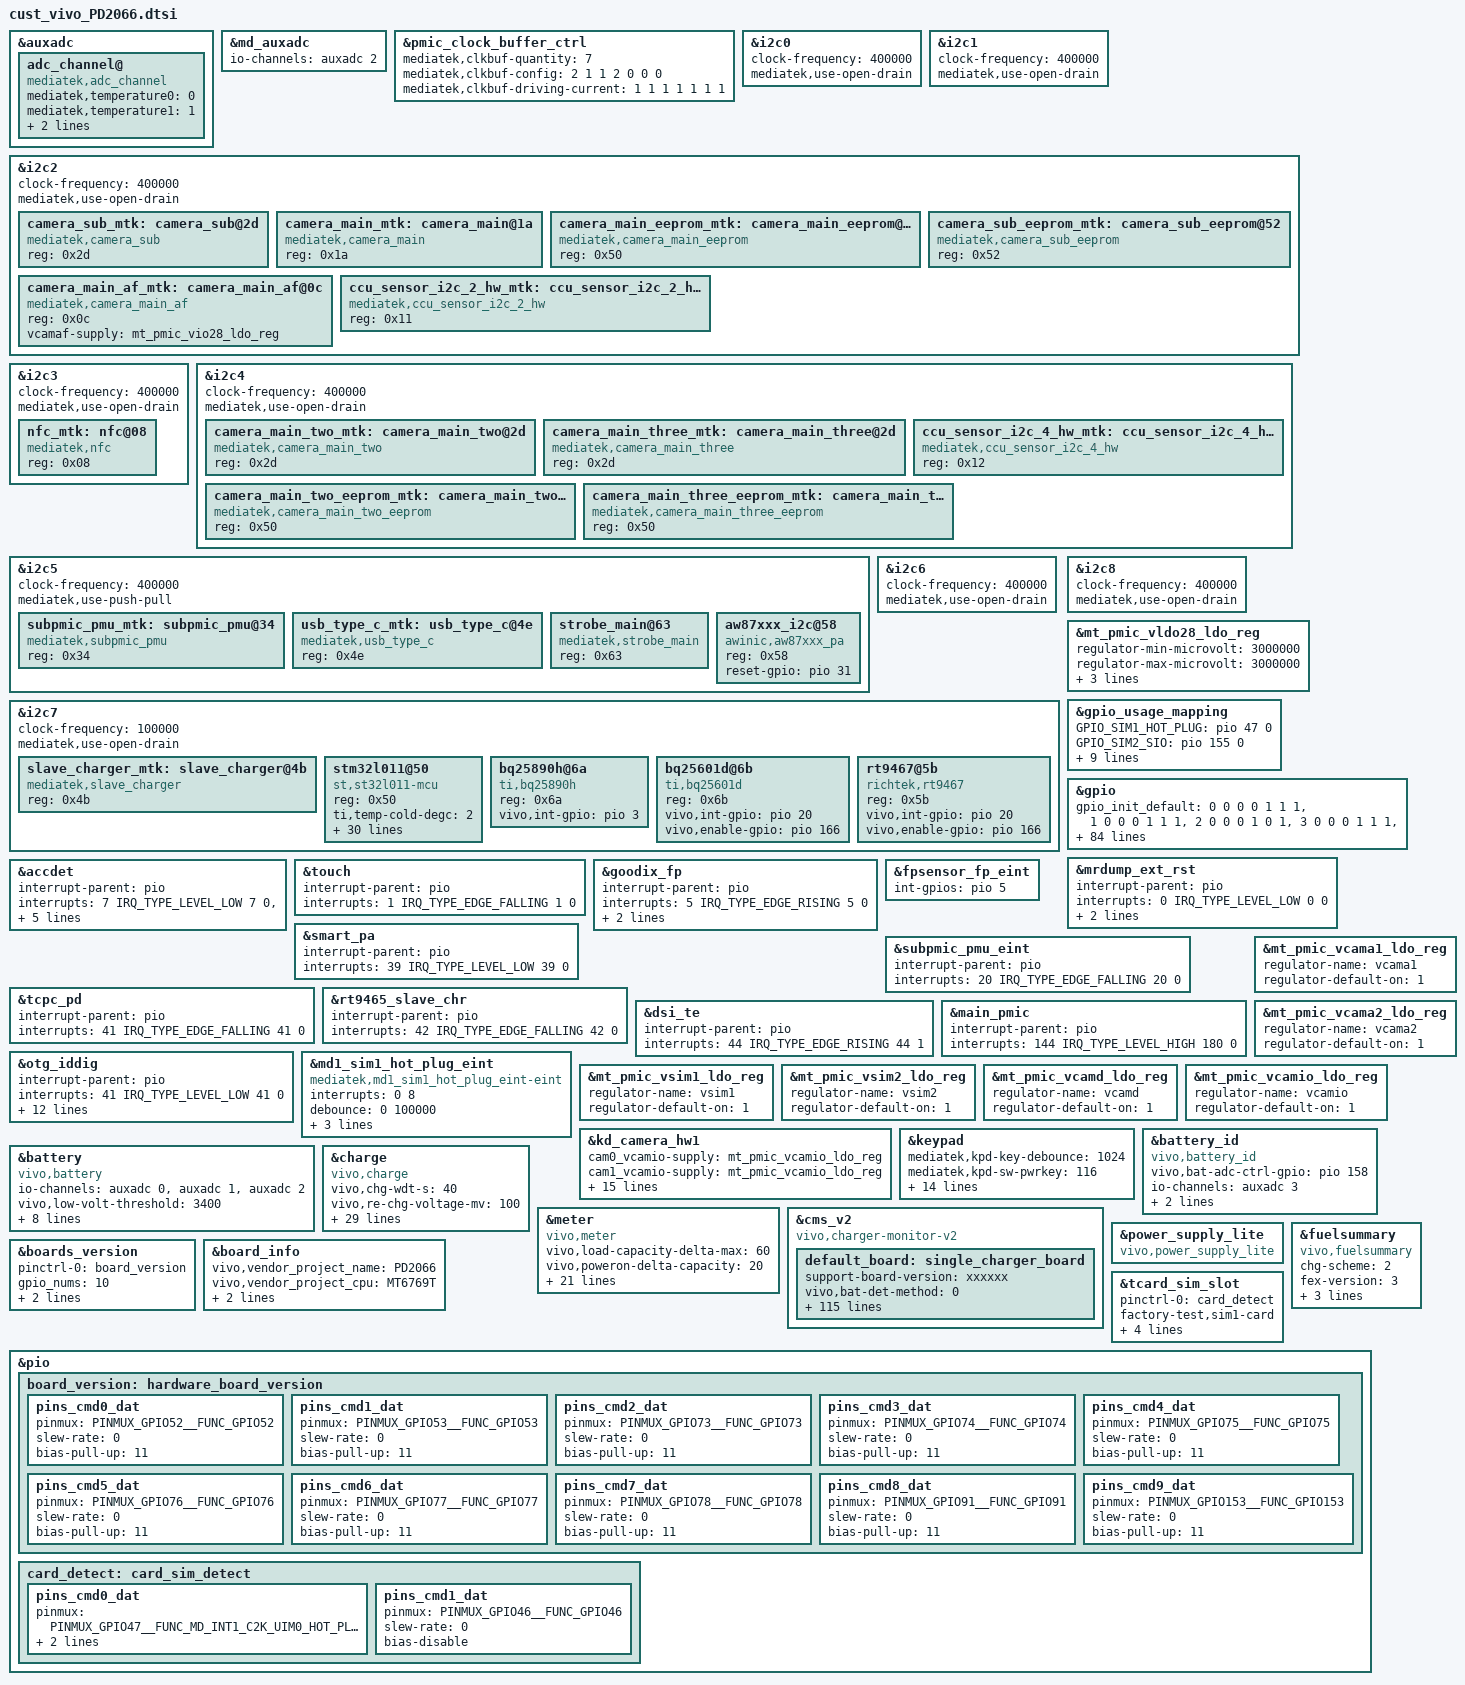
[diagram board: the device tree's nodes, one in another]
/*
 * Generated by MTK SP DrvGen Version: 3.5.160809 for MT6768.
 * 2020-12-22 16:16:35
 * Do Not Modify The File.
 * Copyright Mediatek Inc. (c) 2016.
*/

/*************************
 * ADC DTSI File
*************************/

&auxadc {
	adc_channel@ {
		compatible = "mediatek,adc_channel";
		mediatek,temperature0 = <0>;
		mediatek,temperature1 = <1>;
		mediatek,adc_fdd_rf_params_dynamic_custom_ch = <2>;
		status = "okay";
	};
};
&md_auxadc {
	io-channels = <&auxadc 2>;
};


/*************************
 * CLK_BUF DTSI File
*************************/

&pmic_clock_buffer_ctrl {
	mediatek,clkbuf-quantity = <7>;
	mediatek,clkbuf-config = <2 1 1 2 0 0 0>;
	mediatek,clkbuf-driving-current = <1 1 1 1 1 1 1>;
	status = "okay";
};


/*************************
 * I2C DTSI File
*************************/

&i2c0 {
	#address-cells = <1>;
	#size-cells = <0>;
	clock-frequency = <400000>;
	mediatek,use-open-drain;
};

&i2c1 {
	#address-cells = <1>;
	#size-cells = <0>;
	clock-frequency = <400000>;
	mediatek,use-open-drain;
};

&i2c2 {
	#address-cells = <1>;
	#size-cells = <0>;
	clock-frequency = <400000>;
	mediatek,use-open-drain;
	camera_sub_mtk:camera_sub@2d {
		compatible = "mediatek,camera_sub";
		reg = <0x2d>;
		status = "okay";
	};
	camera_main_mtk:camera_main@1a {
		compatible = "mediatek,camera_main";
		reg = <0x1a>;
		status = "okay";
	};

	camera_main_eeprom_mtk:camera_main_eeprom@50 {
		compatible = "mediatek,camera_main_eeprom";
		reg = <0x50>;
		status = "okay";
	};
        camera_sub_eeprom_mtk:camera_sub_eeprom@52 {
		compatible = "mediatek,camera_sub_eeprom";
		reg = <0x52>;
		status = "okay";
	};
	camera_main_af_mtk:camera_main_af@0c {
		compatible = "mediatek,camera_main_af";
		reg = <0x0c>;
		status = "okay";
	};

	ccu_sensor_i2c_2_hw_mtk:ccu_sensor_i2c_2_hw@11 {
		compatible = "mediatek,ccu_sensor_i2c_2_hw";
		reg = <0x11>;
		status = "okay";
	};

};

&i2c3 {
	#address-cells = <1>;
	#size-cells = <0>;
	clock-frequency = <400000>;
	mediatek,use-open-drain;
	nfc_mtk:nfc@08 {
		compatible = "mediatek,nfc";
		reg = <0x08>;
		status = "okay";
	};



};

&i2c4 {
	#address-cells = <1>;
	#size-cells = <0>;
	clock-frequency = <400000>;
	mediatek,use-open-drain;



	camera_main_two_mtk:camera_main_two@2d {
		compatible = "mediatek,camera_main_two";
		reg = <0x2d>;
		status = "okay";
	};
	
	camera_main_three_mtk:camera_main_three@2d {
		compatible = "mediatek,camera_main_three";
		reg = <0x2d>;
		status = "okay";
	};
	
	ccu_sensor_i2c_4_hw_mtk:ccu_sensor_i2c_4_hw@12 {
		compatible = "mediatek,ccu_sensor_i2c_4_hw";
		reg = <0x12>;
		status = "okay";
	};

	camera_main_two_eeprom_mtk:camera_main_two_eeprom@50 {
		compatible = "mediatek,camera_main_two_eeprom";
		reg = <0x50>;
		status = "okay";
	};

	camera_main_three_eeprom_mtk:camera_main_three_eeprom@50 {
		compatible = "mediatek,camera_main_three_eeprom";
		reg = <0x50>;
		status = "okay";
	};

};

&i2c5 {
	#address-cells = <1>;
	#size-cells = <0>;
	clock-frequency = <400000>;
	mediatek,use-push-pull;
	subpmic_pmu_mtk:subpmic_pmu@34 {
		compatible = "mediatek,subpmic_pmu";
		reg = <0x34>;
		status = "okay";
	};

	usb_type_c_mtk:usb_type_c@4e {
		compatible = "mediatek,usb_type_c";
		reg = <0x4e>;
		status = "okay";
	};
	strobe_main@63 {
		compatible = "mediatek,strobe_main";
		reg = <0x63>;
		status = "okay";
	};

};

&i2c6 {
	#address-cells = <1>;
	#size-cells = <0>;
	clock-frequency = <400000>;
	mediatek,use-open-drain;
};

&i2c7 {
	#address-cells = <1>;
	#size-cells = <0>;
	clock-frequency = <400000>;
	mediatek,use-open-drain;
	slave_charger_mtk:slave_charger@4b {
		compatible = "mediatek,slave_charger";
		reg = <0x4b>;
		status = "okay";
	};

};

&i2c8 {
	#address-cells = <1>;
	#size-cells = <0>;
	clock-frequency = <400000>;
	mediatek,use-open-drain;
};

/* ADD by vsensor team for Psensor LED VLDO28*/
&mt_pmic_vldo28_ldo_reg {
	regulator-min-microvolt = <3000000>;
	regulator-max-microvolt = <3000000>;
	regulator-always-on;
};

/*************************
 * GPIO DTSI File
*************************/

&gpio_usage_mapping {
	GPIO_SIM1_HOT_PLUG = <&pio 47 0>;
	GPIO_SIM2_SIO = <&pio 155 0>;
	GPIO_SIM2_SRST = <&pio 156 0>;
	GPIO_SIM2_SCLK = <&pio 157 0>;
	GPIO_SIM1_SCLK = <&pio 172 0>;
	GPIO_SIM1_SRST = <&pio 173 0>;
	GPIO_SIM1_SIO = <&pio 174 0>;
	GPIO_FDD_BAND_SUPPORT_DETECT_1ST_PIN = <&pio 74 0>;
	GPIO_FDD_BAND_SUPPORT_DETECT_2ND_PIN = <&pio 73 0>;
	GPIO_FDD_BAND_SUPPORT_DETECT_3RD_PIN = <&pio 53 0>;
	GPIO_FDD_BAND_SUPPORT_DETECT_4TH_PIN = <&pio 52 0>;
};

&gpio{
	gpio_init_default = <0 0 0 0 1 1 1>,
		<1 0 0 0 1 1 1>,
		<2 0 0 0 1 0 1>,
		<3 0 0 0 1 1 1>,
		<4 0 0 0 1 0 0>,
		<5 0 0 0 1 0 0>,
		<6 0 0 0 1 0 0>,
		<7 0 0 0 1 0 0>,
		<8 7 0 0 1 0 0>,
		<9 0 0 0 1 0 0>,
		<10 0 0 0 1 1 0>,
		<11 1 0 0 1 0 0>,
		<12 2 0 0 1 0 0>,
		<13 2 0 0 1 0 0>,
		<14 2 1 0 0 0 0>,
		<15 2 1 0 0 0 0>,
		<16 2 1 0 0 0 0>,
		<17 0 0 0 1 0 1>,
		<18 0 0 0 1 1 1>,
		<19 0 0 0 1 1 1>,
		<20 0 0 0 1 1 1>,
		<21 5 0 0 1 0 0>,
		<22 5 0 0 1 0 0>,
		<23 0 1 0 0 0 0>,
		<24 0 0 0 0 0 1>,
		<25 2 0 0 1 0 0>,
		<26 2 0 0 1 0 0>,
		<27 2 1 0 0 0 0>,
		<28 2 0 0 1 1 0>,
		<29 0 1 0 0 0 0>,
		<30 0 1 0 0 0 0>,
		<31 0 0 0 1 0 0>,
		<32 0 1 0 1 0 0>,
		<33 0 1 0 0 0 0>,
		<34 7 0 0 1 0 0>,
		<35 7 0 0 1 0 0>,
		<36 2 1 0 0 0 0>,
		<37 2 1 0 0 0 0>,
		<38 2 1 0 0 0 0>,
		<39 0 0 0 1 1 1>,
		<40 2 0 0 1 0 0>,
		<41 0 0 0 1 1 1>,
		<42 0 0 0 0 0 1>,
		<43 1 1 0 0 0 0>,
		<44 1 0 0 1 0 0>,
		<45 0 1 0 0 0 0>,
		<46 0 0 0 0 0 0>,
		<47 1 0 0 0 0 0>,
		<48 1 0 0 1 1 1>,
		<49 1 0 0 1 1 1>,
		<50 1 0 0 1 1 1>,
		<51 1 0 0 1 1 1>,
		<52 0 0 0 1 1 0>,
		<53 0 0 0 1 1 0>,
		<54 1 0 0 1 0 0>,
		<55 1 0 0 1 0 0>,
		<56 1 0 0 1 0 0>,
		<57 1 0 0 1 0 0>,
		<58 0 0 0 1 0 0>,
		<59 1 0 0 1 0 0>,
		<60 1 0 0 1 0 0>,
		<61 1 0 0 1 0 0>,
		<62 1 0 0 1 0 0>,
		<63 1 0 0 1 0 0>,
		<64 1 0 0 1 0 0>,
		<65 1 0 0 1 0 0>,
		<66 1 0 0 1 0 0>,
		<67 1 0 0 1 0 0>,
		<68 1 0 0 1 0 0>,
		<69 1 0 0 1 0 0>,
		<70 1 0 0 1 0 0>,
		<71 1 0 0 1 0 0>,
		<72 1 0 0 1 0 0>,
		<73 0 0 0 1 1 0>,
		<74 0 0 0 1 1 0>,
		<75 0 0 0 1 1 0>,
		<76 0 0 0 1 1 0>,
		<77 0 0 0 1 1 0>,
		<78 0 0 0 1 1 0>,
		<79 0 0 0 1 0 0>,
		<80 0 0 0 1 0 0>,
		<81 2 0 0 1 1 1>,
		<82 1 0 0 1 1 1>,
		<83 1 0 0 1 1 1>,
		<84 2 0 0 1 1 1>,
		<85 2 0 0 1 0 0>,
		<86 2 1 0 0 0 0>,
		<87 2 1 0 0 0 0>,
		<88 2 1 0 0 0 0>,
		<89 1 0 0 1 1 1>,
		<90 1 0 0 1 1 1>,
		<91 0 0 0 1 1 0>,
		<92 1 1 0 0 0 0>,
		<93 1 0 0 1 1 0>,
		<94 0 1 0 0 0 0>,
		<95 1 0 0 1 1 0>,
		<96 1 1 0 0 0 0>,
		<97 0 1 0 0 0 0>,
		<98 0 1 0 0 0 0>,
		<99 1 1 0 0 0 0>,
		<100 1 1 0 0 0 0>,
		<101 0 1 0 0 0 0>,
		<102 0 1 0 0 0 0>,
		<103 1 0 0 1 1 1>,
		<104 1 0 0 1 1 1>,
		<105 1 0 0 1 1 1>,
		<106 1 0 0 1 1 1>,
		<107 0 1 0 0 0 0>,
		<108 0 0 0 0 0 0>,
		<109 0 1 0 0 0 0>,
		<110 0 1 0 0 0 0>,
		<111 1 1 0 0 0 0>,
		<112 0 0 0 0 0 0>,
		<113 0 0 0 1 0 0>,
		<114 0 0 0 1 0 0>,
		<115 0 0 0 1 0 0>,
		<116 0 0 0 1 0 0>,
		<117 0 0 0 1 0 0>,
		<118 0 0 0 1 0 0>,
		<119 0 0 0 1 0 0>,
		<120 0 0 0 1 0 0>,
		<121 0 0 0 1 0 0>,
		<134 1 0 0 1 0 1>,
		<135 1 1 0 0 0 0>,
		<136 1 1 0 0 0 0>,
		<137 1 1 0 0 0 0>,
		<138 1 1 0 0 0 0>,
		<139 1 1 0 0 0 0>,
		<140 1 0 0 1 0 0>,
		<141 1 0 0 1 0 0>,
		<142 1 0 0 1 0 0>,
		<143 1 0 0 1 0 0>,
		<144 1 0 0 1 0 0>,
		<145 1 1 0 0 0 0>,
		<146 1 1 0 0 0 0>,
		<147 1 1 0 0 0 0>,
		<148 1 1 0 0 0 0>,
		<149 1 1 0 0 0 0>,
		<150 4 0 0 1 1 0>,
		<151 4 1 0 0 0 0>,
		<152 5 0 0 1 1 0>,
		<153 0 0 0 1 1 0>,
		<154 1 1 0 0 0 0>,
		<155 1 0 0 1 1 0>,
		<156 1 1 0 0 0 0>,
		<157 1 1 0 0 0 0>,
		<158 1 1 0 0 0 0>,
		<159 0 1 0 0 0 0>,
		<160 0 1 0 0 0 0>,
		<161 1 0 0 1 1 1>,
		<162 1 0 0 1 1 1>,
		<163 1 0 0 1 1 1>,
		<164 1 0 0 1 1 1>,
		<165 0 1 0 0 0 0>,
		<166 0 1 0 0 0 0>,
		<167 1 0 0 1 0 0>,
		<168 1 0 0 1 0 0>,
		<169 0 1 0 0 0 0>,
		<170 1 0 0 1 1 1>,
		<171 1 1 0 0 0 1>,
		<172 1 1 0 0 0 0>,
		<173 1 1 0 0 0 0>,
		<174 1 0 0 1 1 0>,
		<175 1 0 0 1 1 1>,
		<176 1 0 0 1 1 1>,
		<178 0 1 0 0 0 0>,
		<179 0 1 1 1 1 0>,
		<180 0 0 0 1 0 0>,
		<181 0 0 0 1 0 0>,
		<182 0 0 0 1 0 0>,
		<183 0 0 0 1 0 0>,
		<184 0 0 0 1 0 0>,
		<185 0 0 0 1 0 0>,
		<186 0 0 0 1 0 0>;
};


/*************************
 * EINT DTSI File
*************************/

#include <dt-bindings/interrupt-controller/irq.h>
#include <dt-bindings/interrupt-controller/arm-gic.h>

&mrdump_ext_rst {
	interrupt-parent = <&pio>;
	interrupts = <0 IRQ_TYPE_LEVEL_LOW 0 0>;
	deb-gpios = <&pio 0 0>;
	debounce = <512000>;
	status = "okay";
};
&accdet {
	interrupt-parent = <&pio>;
	interrupts = <7 IRQ_TYPE_LEVEL_LOW 7 0>,
					<6 IRQ_TYPE_LEVEL_LOW 6 0>;
	deb-gpios = <&pio 7 0>;
	deb-rgpios = <&pio 6 0>;
	debounce = <256000>;
	debounce1 = <256000>;
	status = "okay";
};

&touch {
	interrupt-parent = <&pio>;
	interrupts = <1 IRQ_TYPE_EDGE_FALLING 1 0>;
	status = "okay";
};

&goodix_fp {
	interrupt-parent = <&pio>;
	interrupts = <5 IRQ_TYPE_EDGE_RISING 5 0>;
	/*goodix,gpio_vdd_en = <&pio 169 0x0>;*/
	vfp-supply = <&mt_pmic_vcama2_ldo_reg>;
	fpc,enable-wakeup;
	status = "okay";
};
&fpsensor_fp_eint{
	int-gpios = <&pio 5 0x0>;
};

&subpmic_pmu_eint {
	interrupt-parent = <&pio>;
	interrupts = <20 IRQ_TYPE_EDGE_FALLING 20 0>;
	status = "okay";
};

&smart_pa {
	interrupt-parent = <&pio>;
	interrupts = <39 IRQ_TYPE_LEVEL_LOW 39 0>;
	status = "okay";
};

&tcpc_pd {
	interrupt-parent = <&pio>;
	interrupts = <41 IRQ_TYPE_EDGE_FALLING 41 0>;
	status = "okay";
};

&rt9465_slave_chr {
	interrupt-parent = <&pio>;
	interrupts = <42 IRQ_TYPE_EDGE_FALLING 42 0>;
	status = "okay";
};

&dsi_te {
	interrupt-parent = <&pio>;
	interrupts = <44 IRQ_TYPE_EDGE_RISING 44 1>;
	status = "okay";
};

&main_pmic {
	interrupt-parent = <&pio>;
	interrupts = <144 IRQ_TYPE_LEVEL_HIGH 180 0>;
	status = "okay";
};

&otg_iddig {
    interrupt-parent = <&pio>;
    interrupts = <41 IRQ_TYPE_LEVEL_LOW 41 0>;
   
    usbid-num = <&pio 41 1>;
	mtk,otg_chip_compatible_mode;

    pinctrl-names = "iddig_default", "iddig_otg_gpio", "iddig_otg_gpio_pull_down", "otg_gpio_pull_high", "otg_gpio_pull_low", "otg_gpio_pull_in", 
		"otg_gpio_pull1_high", "otg_gpio_pull1_low", "otg_gpio_pull1_in", "iddig_otg_init";
    pinctrl-0 = <&iddig_default>;
    pinctrl-1 = <&gpio41_mode0_gpio>;
	pinctrl-2 = <&gpio41_mode0_gpio_pull_down>;
    pinctrl-3 = <&gpio30_otg_pull_high>;
    pinctrl-4 = <&gpio30_otg_pull_low>;
    pinctrl-5 = <&gpio30_otg_pull_in>;
    pinctrl-6 = <&gpio29_otg_pull1_high>;
    pinctrl-7 = <&gpio29_otg_pull1_low>;
    pinctrl-8 = <&gpio29_otg_pull1_in>;
    pinctrl-9 = <&gpio41_mode1_iddig>;
	
    status = "okay";
};

/*************************
 * MD1_EINT DTSI File
*************************/

&md1_sim1_hot_plug_eint {
	compatible = "mediatek,md1_sim1_hot_plug_eint-eint";
	interrupts = <0 8>;
	debounce = <0 100000>;
	dedicated = <0 0>;
	src_pin = <0 1>;
	sockettype = <0 0>;
	status = "okay";
};



/*************************
 * PMIC DTSI File
*************************/

&mt_pmic_vcama1_ldo_reg {
	regulator-name = "vcama1";
	regulator-default-on = <1>; /* 0:skip, 1: off, 2:on */
	status = "okay";
};
&mt_pmic_vcama2_ldo_reg {
	regulator-name = "vcama2";
	regulator-default-on = <1>; /* 0:skip, 1: off, 2:on */
	status = "okay";
};
&mt_pmic_vsim1_ldo_reg {
	regulator-name = "vsim1";
	regulator-default-on = <1>; /* 0:skip, 1: off, 2:on */
	status = "okay";
};
&mt_pmic_vsim2_ldo_reg {
	regulator-name = "vsim2";
	regulator-default-on = <1>; /* 0:skip, 1: off, 2:on */
	status = "okay";
};
&mt_pmic_vcamd_ldo_reg {
	regulator-name = "vcamd";
	regulator-default-on = <1>; /* 0:skip, 1: off, 2:on */
	status = "okay";
};
&mt_pmic_vcamio_ldo_reg {
	regulator-name = "vcamio";
	regulator-default-on = <1>; /* 0:skip, 1: off, 2:on */
	status = "okay";
};
&mt_pmic_vldo28_ldo_reg {
	regulator-name = "vldo28";
	regulator-default-on = <1>; /* 0:skip, 1: off, 2:on */
	status = "okay";
};

&kd_camera_hw1 {
	cam0_vcamio-supply = <&mt_pmic_vcamio_ldo_reg>;
	cam1_vcamio-supply = <&mt_pmic_vcamio_ldo_reg>;
	cam2_vcamio-supply = <&mt_pmic_vcamio_ldo_reg>;
	cam4_vcamio-supply = <&mt_pmic_vcamio_ldo_reg>;
	//cam0_vcamaf_def-supply = <&mt_pmic_vio28_ldo_reg>;

	cam0_vcamd-supply = <&mt_pmic_vcamd_ldo_reg>;
	cam1_vcamd-supply = <&mt_pmic_vcamd_ldo_reg>;


	cam0_vcama-supply = <&mt_pmic_vcama1_ldo_reg>;
	cam1_vcama-supply = <&mt_pmic_vcama1_ldo_reg>;
	cam2_vcama-supply = <&mt_pmic_vcama1_ldo_reg>;
	cam4_vcama-supply = <&mt_pmic_vcama1_ldo_reg>;

	cam0_enable_sensor = "ov13b10PD2066A_mipi_raw ov13b10v1PD2066A_mipi_raw";
	cam1_enable_sensor = "s5k4h7yxPD2066A_mipi_raw s5k4h7yxv1PD2066A_mipi_raw";
        cam2_enable_sensor = "gc02m1bPD2066A_mipi_mono";
        cam4_enable_sensor = "ov02b10PD2066A_mipi_raw ov02b10v1PD2066A_mipi_raw";
	status = "okay";
};

&camera_main_af_mtk {
	vcamaf-supply = <&mt_pmic_vio28_ldo_reg>;
	status = "okay";
};


/*************************
 * POWER DTSI File
*************************/



/*************************
 * KPD DTSI File
*************************/

&keypad {
	mediatek,kpd-key-debounce = <1024>;
	mediatek,kpd-sw-pwrkey = <116>;
	mediatek,kpd-hw-pwrkey = <8>;
	mediatek,kpd-sw-rstkey  = <114>;
	mediatek,kpd-hw-rstkey = <17>;
	mediatek,kpd-use-extend-type = <0>;
	/*HW Keycode [0~71] -> Linux Keycode*/
	mediatek,kpd-hw-map-num = <72>;
	mediatek,kpd-hw-init-map = <115 0 0 0 0 0 0 0 0 0 0 0 0 0 0 0 0 0 0 0 0 0 0 0 0 0 0 0 0 0 0 0 0 0 0 0 0 0 0 0 0 0 0 0 0 0 0 0 0 0 0 0 0 0 0 0 0 0 0 0 0 0 0 0 0 0 0 0 0 0 0 0 >;
	mediatek,kpd-pwrkey-eint-gpio = <0>;
	mediatek,kpd-pwkey-gpio-din  = <0>;
	mediatek,kpd-hw-dl-key0 = <17>;
	mediatek,kpd-hw-dl-key1 = <0>;
	mediatek,kpd-hw-dl-key2 = <8>;
	mediatek,kpd-hw-recovery-key = <17>;
	mediatek,kpd-hw-factory-key = <0>;
	status = "okay";
};

/* fuxi add for battery&charge start */
&battery_id {
	status = "okay";
	compatible = "vivo,battery_id";

	vivo,bat-adc-ctrl-gpio = <&pio 158 0>;

	io-channels = <&auxadc 3>;
	io-channel-names = "battery_id_adc";

	vivo,bat-name = "B-O5 LW 5000","B-O5 LW 5000","B-O5 SDI 5000","B-O5 ATL 5000","UNKOWN","UNKOWN";
};

&battery {
	status = "okay";
	compatible = "vivo,battery";

	io-channels = <&auxadc 0>,
		<&auxadc 1>,
		<&auxadc 2>;
	io-channel-names = "primary_board_therm",
		"pa_therm",
		"parallel_board_therm";

	vivo,low-volt-threshold = <3400>;
	vivo,soft-rise-percent = <96>;
	vivo,soft-rise-cumulative = <3>;
	vivo,soft-rise-keep-cumulative = <10>;
	vivo,percnet-sync-delta = <5>;
	vivo,percnet-sync-cumulative = <9>;
	vivo,full-sync-cumulative = <3>;
	vivo,soft-term-percent = <99>;
	vivo,soft-term-cumulative = <48>;
};

&charge {
	status = "okay";
	compatible = "vivo,charge";

	vivo,chg-wdt-s = <40>;
	vivo,re-chg-voltage-mv = <100>;
	vivo,prechg-voltage-mv = <3000>;
	vivo,iprechg-current-ma = <300>;
	vivo,iterm-current-ma = <256>;
	vivo,vreg-voltage-mv = <4430>;
	vivo,vindpm-voltage-mv = <4600>;
	vivo,sys-voltage-min-mv= <3300>;
	vivo,boostv-voltage-mv = <5150>;
	vivo,boostv-ilimit-ma = <1500>;
	vivo,ovp-voltage-mv = <15000>;

	vivo,battery-id-vreg-mv = <4430 4430 4430 4430 4430 4430>;
	/*
	 * 0  auto detect charging
	 * 1  vivo-normal chargine
	 * 2  vivo-single engine charging
	 * 3  vivo-dual engine charging
	 * 4  vivo-flash charging
	*/
	vivo,charge-scheme = <0>;
	vivo,direct-charger-enable;

	/*
	 * SUPPORTED_ADAPTER_DEFAULT = 0,
	 * SUPPORTED_ADAPTER_VIVO_LV_DCHG_5V_4500MA = 1,
	 * SUPPORTED_ADAPTER_VIVO_HV_DCHG_10V_2250MA = 2,
	 * SUPPORTED_ADAPTER_QC20__9V_2000MA = 3,
	 * SUPPORTED_ADAPTER_VIVO_HV_DCHG_10V_4000MA = 4,
	 * SUPPORTED_ADAPTER_MAX,
	 */
	vivo,supported-adapter = <3>;

	//parameter for 9V2A
	vivo,primary-ichg-max-ma = <2240>;
	vivo,parallel-ichg-max-ma = <1740>;

	vivo,flashchg-spec-ma = <2000 3300 6000>;
	vivo,fastchg-spec-ma = <2000 2100 3800>;
	vivo,normalchg-spec-ma = <2000 1500 2300>;

	/* 0---PMIC; 1---CHGIC */
	vivo,vbus-detect-source = <1>;

	vivo,usboe-gpio = <&pio 178 0>;

	/*ffc*/
	//vivo,ffc-enable;
	vivo,ffc-iterm-ma = <(-750)>;
	vivo,ffc-vreg-mv = <4500>;
	vivo,ffc-temperature-range = <150 450>;
	vivo,ffc-full-vbat-table-size = <3>;
	vivo,ffc-full-vbat-table = <4480 4490 4460>;
	vivo,ffc-full-ibat-table-size = <2>;
	vivo,ffc-full-ibat-table = <150 349 (-980)>,
		<350 449 (-1176)>;
};

&meter {
	status = "okay";
	compatible = "vivo,meter";

	vivo,load-capacity-delta-max = <60>;
	vivo,poweron-delta-capacity = <20>;
	vivo,poweron-low-capacity = <3>;
	vivo,volt-car-delta = <8>;
	vivo,car-volt-delta = <6>;
	vivo,meter-res-compesate = <10>;
	vivo,ocv-board-compesate = <0>;

	/* 0---AGING_UNSUPPORTED; 1---DRIVER_SUPPORTED; 2---USPACE_SUPPORTED */
	vivo,battery-aging-support = <2>;

	vivo,capacity-mAh = <4910>;
	/*COLD_CHG COLD_DISCHG NORMAL_CHG NORMAL_DISCHG*/
	vivo,car-tune-value = <1045 1000 1045 1000>,
		<1045 1000 1045 1000>,
		<1045 1000 1045 1000>,
		<1045 1000 1045 1000>,
		<1045 1000 1045 1000>,
		<1045 1000 1045 1000>;
	vivo,bats-qmax = <3480 3930 4250 4580 4660>,
		<3320 3880 4590 4680 4750>,
		<3030 3480 4290 4560 4630>,
		<3830 4080 4400 4600 4700>,
		<4500 4668 4762 4851 4821>,
		<4500 4668 4762 4851 4821>;

	/* car-tune adjust remap */
	vivo,car-tune-adjust-enable;
	vivo,car-tune-adjust-size = <3>;
	vivo,car-tune-adjust-table = <0 10 (360) 6>,
		<11 20 (-35) 7>,
		<21 100 (-45) 8>;

	#include "bat_setting/PD2066_battery_table.dtsi"
};

&cms_v2 {
	compatible = "vivo,charger-monitor-v2";
	status = "okay";

	default_board: single_charger_board {
		/*default board: keep in xxxxxx*/
		support-board-version = "xxxxxx";

		vivo,bat-det-method = <0>;//r:0, rc:1, eprom:2, ex-fg:3
		//vivo,bat-id-gpio = <&pio 158 0>;

		//vivo,no-bat-warning;
		//vivo,no-chg-timeout;
		vivo,chg-timeout-mins = <900>;

		//high temperature charger current control enable
		vivo,htccc-enable;
		vivo,htccc-data = <46 55 4100000 100000>;

		//vivo,fbon-scale-enable;/*disable default*/
		vivo,fbon-scale-data = <2 100 100>;

		//vivo,switch-scale-enable;/*disable from rom4.0*/
		vivo,switch-scale-data = <75 53>;

		vivo,calling-scale-enable;
		vivo,calling-scale-data = <100 21>;/*ibat:3900 * 0.54 = 2106,more than 1500,not exit dchg*/
		vivo,calling-dchg-disable;

		vivo,weixin-calling-scale-enable;
		vivo,weixin-calling-scale-data = <100 112>;/*5000mA*/

		//vivo,fixed-scale-enable;
		vivo,fixed-scale-data = <120 3800 0>;/*dchg fixed time adjust the max ibat,disable default*/

		/*data processing : batt-temp*/
		vivo,dp-batt-temp-enable;
		vivo,dp-batt-temp-data = <100>;

		/* charging current for devices in exhibition mode */
		vivo,exhibition-mode-current-primary = <2048>;
		vivo,exhibition-mode-current-parallel = <0>;

		/*default tc parameter*/
		//single charger ibat scale base on temperature battery cell info:1C/1.2C 3960mah
		/* tmin, tmax, data, volt1, data_ex1, volt2, data_ex2. */
		vivo,normal-tc-row-col = <10 7>;
		vivo,normal-tc-data = <550 8888 0 0 0 0 0>,
			<450 549 50 0 0 0 0>,
			<200 449 100 4200000 70 0 0>,
			<150 199 100 4200000 70 0 0>,
			<100 149 70 4200000 50 0 0>,
			<50 99 50 4200000 30 0 0>,
			<0 49 50 4200000 30 0 0>,
			<(-8888) (-1) 0 0 0 0 0>,
			<(-8888) (-1) 0 0 0 0 0>,
			<(-8888) (-1) 0 0 0 0 0>;

		/*flash tc parameter*/
		vivo,flash-normal-tc-row-col = <10 7>;
		vivo,flash-normal-tc-data = <550 8888 0 0 0 0 0>,
			<450 549 50 0 0 0 0>,
			<200 449 223 4390000 179 4400000 134>,
			<150 199 203 4250000 152 0 0>,
			<100 149 120 4200000 100 0 0>,
			<50 99 70 4200000 50 0 0>,
			<0 49 50 4380000 50 0 0>,
			<(-50) (-1) 30 0 0 0 0>,
			<(-100) (-51) 20 0 0 0 0>,
			<(-8888) (-101) 0 0 0 0 0>;

		/*adjust fastchg base on board temperature and fb off*/
		vivo,intell-charge-enable;
		vivo,parallel-temp-enable = <1 1>;//<x y> x:fb-on y:fb-off

		/* Flash charge fb-on intell param */
		vivo,primary-fbon-tc-row-col = <6 3>;
		vivo,primary-fbon-tc-data = <460 8888 1600>,
			<410 459 2600>,
			<400 409 3000>,
			<390 399 3300>,
			<371 389 3700>,
			<(-8888) 370 6000>;

		vivo,parallel-fbon-tc-row-col = <1 3>;
		vivo,parallel-fbon-tc-data = <(-8888) 8888 0>;


		/* Flash charge fb-off intell param */
		vivo,primary-fboff-tc-row-col = <6 3>;
		vivo,primary-fboff-tc-data = <450 8888 1800>,
			<390 449 3000>,
			<380 389 3400>,
			<376 379 3700>,
			<371 375 4100>,
			<(-8888) 370 6000>;
		vivo,parallel-fboff-tc-row-col = <1 3>;
		vivo,parallel-fboff-tc-data = <(-8888) 8888 0>;


		/* 9v Fast charge fb-on intell param */
		vivo,9v-primary-fbon-tc-row-col = <6 3>;
		vivo,9v-primary-fbon-tc-data = <446 8888 512>,
			<421 445 900>,
			<401 420 1100>,
			<391 400 1300>,
			<371 390 1400>,
			<(-8888) 370 1600>;
		vivo,9v-parallel-fbon-tc-row-col = <6 3>;
		vivo,9v-parallel-fbon-tc-data = <446 8888 512>,
			<421 445 700>,
			<401 420 900>,
			<391 400 1100>,
			<371 390 1300>,
			<(-8888) 370 1500>;
		// second parallel parameter, for rt9467
		vivo,9v-2nd-parallel-fbon-tc-row-col = <6 3>;
		vivo,9v-2nd-parallel-fbon-tc-data = <451 8888 512>,
			<431 450 800>,
			<401 430 1000>,
			<391 400 1100>,
			<371 390 1300>,
			<(-8888) 370 1500>;

		/* 9v Fast charge fb-off intell param */
		vivo,9v-primary-fboff-tc-row-col = <7 3>;
		vivo,9v-primary-fboff-tc-data = <451 8888 700>,
			<431 450 1024>,
			<411 430 1200>,
			<391 410 1500>,
			<371 390 1600>,
			<361 370 1800>,
			<(-8888) 360 2048>;
		vivo,9v-parallel-fboff-tc-row-col = <7 3>;
		vivo,9v-parallel-fboff-tc-data = <441 8888 750>,
			<431 440 1050>,
			<406 430 1100>,
			<391 405 1300>,
			<376 390 1450>,
			<361 375 1550>,
			<(-8888) 360 1700>;
		// second parallel parameter, for rt9467
		vivo,9v-2nd-parallel-fboff-tc-row-col = <7 3>;
		vivo,9v-2nd-parallel-fboff-tc-data = <441 8888 750>,
			<431 440 1050>,
			<406 430 1100>,
			<391 405 1300>,
			<376 390 1450>,
			<361 375 1550>,
			<(-8888) 360 1700>;


		/* 5v Normal charge fb-on intell param */
		vivo,5v-primary-fbon-tc-row-col = <7 3>;
		vivo,5v-primary-fbon-tc-data = <486 8888 512>,
			<476 485 700>,
			<461 475 1000>,
			<431 460 1408>,
			<411 430 1600>,
			<381 410 1800>,
			<(-8888) 380 2048>;
		vivo,5v-parallel-fbon-tc-row-col = <1 3>;
		vivo,5v-parallel-fbon-tc-data = <(-8888) 8888 0>;

		/* 5v Normal charge fb-off intell param */
		vivo,5v-primary-fboff-tc-row-col = <6 3>;
		vivo,5v-primary-fboff-tc-data = <491 8888 512>,
			<471 490 1024>,
			<451 470 1216>,
			<431 450 1600>,
			<411 430 1800>,
			<(-8888) 410 2048>;
		vivo,5v-parallel-fboff-tc-row-col = <1 3>;
		vivo,5v-parallel-fboff-tc-data = <(-8888) 8888 0>;

		// Direct charging param
		vivo,direct-charger-enable;//porting_check
		vivo,ex-bms-psy-name = "bq_bms";

		// bat_baord, usb_conn, pcb_conn(master_bat_conn), bat_conn
		vivo,dchg-ntc-protect-enable;
		vivo,dchg-ntc-protect-data = <750 800 850 850>;

		vivo,adapter-cooldown-data = <900 850 3400>;
		/*adapter power derate*/
		vivo,adapter-power-derate-enable;

		/* usb connecter protect param
		 * USB_PROTECT_NONE = 0,
		 * USB_CONN_TEMP_HEAT_PROTECT = BIT(0),
		 * USB_ID_PROTECT = BIT(1),
		 */
		vivo,usb-connecter-protect-enable = <1>;
		vivo,usb-id-protect-data= <1100 1547 500>;/* 500K, 2M, fcc */
		vivo,usb-conn-heat-protect-data-row-col = <2 4>;
		vivo,usb-conn-heat-protect-data= <260 8888 670 620>,
			<(-8888) 259 570 520>;

		/* usb conn protect function */
		vivo,usb-conn-pro-enable;
		vivo,usb-conn-pro-gpio = <&pio 159 0>;

		/*
		 * max vbus of adapter:11v, max ibus of adapter:5A
		 * min voltage of battery for half chg:3500mV,max voltage of battery for half charge:4100mV,
		 * 5V2A charge min current threshold: 1000mA,5V2A charge max current threshold:2100mA,
		 * flash charge min current threshold:5000mA,flash charge max current threshold:11000mA
		 */

		/*default parameter*/
		vivo,charge-param-judge-threshold = <9 2 3500 4300 1000 2100 2100 4600>;
		/* factory mode charging test param */
		vivo,charge-test-param-row-col = <12 3>;
		vivo,charge-test-param-data = <0 0 5500>, /* cable resistance, min value, max value */
		        <0 0 5500>, /* master ibus, min ibus, max ibus */
		        <0 0 5500>, /* slave ibus, min ibus, max ibus */
		        <1 20 40>, /* batt therm ntc, min value, max value */
		        <1 20 45>, /* board therm ntc, min value, max value */
		        <0 20 50>, /* sub charger ntc, min value, max value */
		        <0 20 45>, /* usb con ntc, min value, max value */
		        <0 20 45>, /* usb con 1 ntc, double usb NTC, min value, max value */
		        <0 20 45>, /* bat btb master ntc, min value, max value */
		        <0 20 50>, /* bat btb sub ntc, min value, max value */
		        <0 20 50>, /* bat board ntc, min value, max value */
		        <0 20 50>; /* wireless charge coil ntc, min value, max value */

		/*flash parameter*/
		vivo,flash-charge-param-judge-threshold = <11 3 3500 4100 1000 2200 4000 6100>;
		/* factory mode charging test param */
		vivo,flash-charge-test-param-row-col = <12 3>;
		vivo,flash-charge-test-param-data = <1 0 5500>, /* cable resistance, min value, max value */
		        <1 0 5500>, /* master ibus, min ibus, max ibus */
		        <0 0 5500>, /* slave ibus, min ibus, max ibus */
		        <1 20 40>, /* batt therm ntc, min value, max value */
		        <1 20 45>, /* board therm ntc, min value, max value */
		        <0 20 50>, /* sub charger ntc, min value, max value */
		        <1 20 45>, /* usb con ntc, min value, max value */
		        <0 20 45>, /* usb con 1 ntc, double usb NTC, min value, max value */
		        <1 20 45>, /* bat btb master ntc, min value, max value */
		        <0 20 50>, /* bat btb sub ntc, min value, max value */
		        <0 20 50>, /* bat board ntc, min value, max value */
		        <0 20 50>; /* wireless charge coil ntc, min value, max value */
	};
};

&power_supply_lite {
	status = "okay";
	compatible = "vivo,power_supply_lite";
};

&fuelsummary {
	status = "okay";
	compatible = "vivo,fuelsummary";

	/************************************************************
	 *
	 *  0   vivo-fastchg
	 *  1   qcom-dualchg
	 *  2   mtk-dualchg
	 *  3   qcom-normchg
	 *  4   mtk-normchg
	 *
	 ***********************************************************/
	chg-scheme = <2>;
	fex-version = <3>;
	fbon-ibat = <(-900)>;
	fboff-ibat = <(-1000)>;

	/* 0---AGING_UNSUPPORTED; 1---DRIVER_SUPPORTED; 2---USPACE_SUPPORTED */
	vivo,battery-aging-support = <2>;
};

&i2c7 {
	#address-cells = <1>;
	#size-cells = <0>;
	status = "okay";
	clock-frequency = <100000>;

	stm32l011@50 {
		compatible = "st,st32l011-mcu";
		reg = <0x50>;

		//vpower-ldo-supply = <&mt_pmic_vcn33_2_wifi_ldo_reg>;
		//vivo,power-gpio = <&pio 27 0>;//ZC_LDO_EN
		//vivo,int-gpio = <&pio 6 0>;//MCU_INT_AP
		//vivo,usbsel-gpio = <&pio 13 0>;//USB_SW_EN
		//vivo,shift-en-gpio = <&pio 12 0>;//SHIFT_EN
		//vivo,chg-version-gpio = <&pio 64 0>;//°æ±¾Ê¶±ð
		//vivo,sbu-pwr-gpio = <&pio 20 0>;
		ti,temp-cold-degc = <2>;
		ti,temp-hot-degc = <43>;
		vivo,total-limit-max-ma = <6000>;
		vivo,bigdata-collect-time-limit = <95>;//seconds
		vivo,direct-charger-enable;//porting_check

		/*FFC charge: */
		vivo,ffc-support;
		vivo,ffc-temperature-range = <150 450>;
		//vivo,ffc-param-tuning-enable = <1963>;
		vivo,ffc-cc-to-cv-ibat-thr-rc = <1 3>;
		/*<Tmin Tmax current>*/
		vivo,ffc-cc-to-cv-ibat-thr-table = <150 450 4900>;
		vivo,ffc-dchg-cv-mv-rc = <3 2>;
		/*btb_cv,fg_cv*/
		vivo,ffc-dchg-cv-mv-table = <4450 4430>,/*default*/
			<4500 4480>,/*single_charging*/
			<4500 4480>;/*dual_charging*/

		//vivo,cout-int-gpio = <&pio 5 0>;

		vivo,sbu-cable-id-detect-enable;

		vivo,bat-board-temp-enable = <0>;
		vivo,usb-conn-temp-enable = <1>;
		vivo,bat-conn-temp-enable = <1>;

		vivo,master-bat-conn-temp-enable = <2>;
		vivo,dchg-exit-ntc-threshold = <700 650 700 700 1200>;

		/* BQ25970_SINGLE_DCHG:
		 * DCHG_SINGLE_TYPE_22P5W = 0,
		 * DCHG_SINGLE_TYPE_33W = 1,
		 * DCHG_SINGLE_TYPE_44W = 2,
		 * BQ25970_DUAL_DCHG:DCHG_DUAL_TYPE_44W = 3,
		 */
		vivo,dchg-supported-type = <1>;
		/*adapter power derate*/
		vivo,adapter-power-derate-enable;

		//vivo,single-charger-enable;
		vivo,adapter-sha-encryption;

		io-channels = <&auxadc 4>,
			<&auxadc 5>;

		io-channel-names = "sbu2_cable_id_adc",
			"sbu1_cable_id_adc";

		/*cable r limit table :
		  <rmin,rmax, dchg_ibus_max, cable_id_type, limit_count>
		  cable_id_type: 0:effective cable id, 1:other(default) cable id
		 */
		vivo,cable-r-limit-table-rc = <9 5>;
		vivo,cable-r-limit-table = <(-8888) 271 4000 0 0>,
			<272 329 3000 0 0>,
			<330 394 2250 0 0>,
			<395 505 1800 0 0>,
			<506 8888 0 0 0>,
			<(-8888) 329 3000 1 0>,
			<330 394 2250 1 0>,
			<395 505 1800 1 0>,
			<506 8888 0 1 0>;

		/*load firmware profile*/
		vivo,fw-id-range-pct = <100>;
		#include "bat_setting/mcu-firmware-data-33w.dtsi"
		#include "bat_setting/mcu-firmware-data-44w.dtsi"
	};

	bq25890h@6a {
		compatible = "ti,bq25890h";
		reg = <0x6a>;

		vivo,int-gpio = <&pio 3 0>;
	};

	bq25601d@6b {
		compatible = "ti,bq25601d";
		reg = <0x6b>;

		vivo,int-gpio = <&pio 20 0>;
		vivo,enable-gpio = <&pio 166 0>;
	};

	rt9467@5b {
		compatible = "richtek,rt9467";
		reg = <0x5b>;

		//vivo,int-gpio = <&pio 3 0>;//main ic second

		vivo,int-gpio = <&pio 20 0>;
		vivo,enable-gpio = <&pio 166 0>;
	};
};
/* fuxi add for battery&charge end */

/*vivo audio team add for speaker begin*/
&i2c5{
		aw87xxx_i2c@58 {
			compatible = "awinic,aw87xxx_pa";
			reg = <0x58>;
			reset-gpio = <&pio 31 0>;
			status = "okay";
		};
};
/*vivo audio team add for speaker end*/

&boards_version {
	pinctrl-names = "default";
	pinctrl-0 = <&board_version>;
	gpio_nums = <10>;
	gpios = <52 53 73 74 75 76 77 78 91 153>;
	gpios_start = <&pio 52 0>;
};

&board_info {
	vivo,vendor_project_name = "PD2066";
	vivo,vendor_project_cpu = "MT6769T";
	vivo,vendor_project_freq = "2.0";
	vivo,vendor_project_cpunum = <8>;
};

&tcard_sim_slot {
	pinctrl-names = "default";
	pinctrl-0 = <&card_detect>;
        factory-test,sim1-card;
        factory-test,sim2-card;
	//factory-test,tf-card;
	vivo,new_card_detect;
        card-detect-sim1,gpios = <&pio 47 0x0>;
        card-detect-sim2,gpios = <&pio 46 0x0>;
	//card-detect-tf-card,gpios = <&pio 18 0x0>;
};

&pio {
	board_version: hardware_board_version {
		pins_cmd0_dat {
			pinmux = <PINMUX_GPIO52__FUNC_GPIO52>;
			slew-rate = <0>;
			bias-pull-up = <11>;
		};
		pins_cmd1_dat {
			pinmux = <PINMUX_GPIO53__FUNC_GPIO53>;
			slew-rate = <0>;
			bias-pull-up = <11>;
		};
		pins_cmd2_dat {
			pinmux = <PINMUX_GPIO73__FUNC_GPIO73>;
			slew-rate = <0>;
			bias-pull-up = <11>;
		};
		pins_cmd3_dat {
			pinmux = <PINMUX_GPIO74__FUNC_GPIO74>;
			slew-rate = <0>;
			bias-pull-up = <11>;
		};
		pins_cmd4_dat {
			pinmux = <PINMUX_GPIO75__FUNC_GPIO75>;
			slew-rate = <0>;
			bias-pull-up = <11>;
		};
		pins_cmd5_dat {
			pinmux = <PINMUX_GPIO76__FUNC_GPIO76>;
			slew-rate = <0>;
			bias-pull-up = <11>;
		};
		pins_cmd6_dat {
			pinmux = <PINMUX_GPIO77__FUNC_GPIO77>;
			slew-rate = <0>;
			bias-pull-up = <11>;
		};
		pins_cmd7_dat {
			pinmux = <PINMUX_GPIO78__FUNC_GPIO78>;
			slew-rate = <0>;
			bias-pull-up = <11>;
		};
		pins_cmd8_dat {
			pinmux = <PINMUX_GPIO91__FUNC_GPIO91>;
			slew-rate = <0>;
			bias-pull-up = <11>;
		};	
		pins_cmd9_dat {
			pinmux = <PINMUX_GPIO153__FUNC_GPIO153>;
			slew-rate = <0>;
			bias-pull-up = <11>;
		};
	};

	card_detect: card_sim_detect {
		pins_cmd0_dat {
			pinmux = <PINMUX_GPIO47__FUNC_MD_INT1_C2K_UIM0_HOT_PLUG>;
			slew-rate = <0>;
			bias-disable;
		};
		pins_cmd1_dat {
			pinmux = <PINMUX_GPIO46__FUNC_GPIO46>;
			slew-rate = <0>;
			bias-disable;
		};
		//pins_cmd2_dat {
		//	pinmux = <PINMUX_GPIO18__FUNC_GPIO18>;
		//	slew-rate = <0>;
		//	bias-disable;
		//};
	};
};
